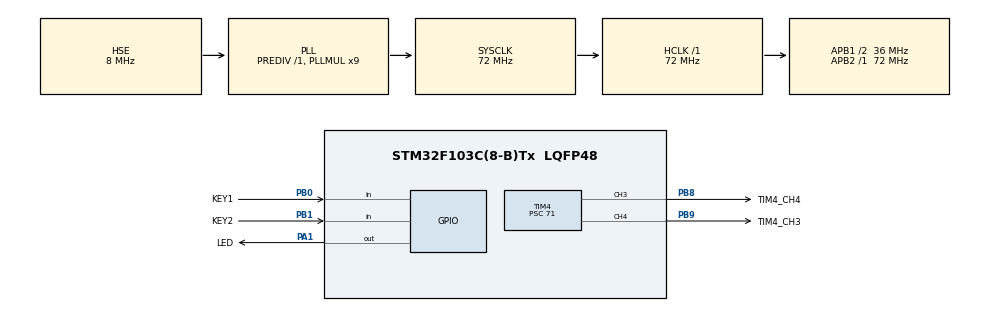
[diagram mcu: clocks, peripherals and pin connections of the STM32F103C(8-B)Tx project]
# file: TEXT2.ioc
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Mcu.Family=STM32F1
Mcu.Name=STM32F103C(8-B)Tx
Mcu.Package=LQFP48
NVIC.PriorityGroup=NVIC_PRIORITYGROUP_4
PA1.GPIO_Label=LED
PA1.PinState=GPIO_PIN_SET
PA1.Signal=GPIO_Output
PB0.GPIO_Label=KEY1
PB0.GPIO_PuPd=GPIO_PULLUP
PB0.Signal=GPIO_Input
PB1.GPIO_Label=KEY2
PB1.GPIO_PuPd=GPIO_PULLUP
PB1.Signal=GPIO_Input
PB8.GPIO_Label=TIM4_CH4
PB8.Signal=S_TIM4_CH3
PB9.GPIO_Label=TIM4_CH3
PB9.Signal=S_TIM4_CH4
PD0-OSC_IN.Mode=HSE-External-Oscillator
PD0-OSC_IN.Signal=RCC_OSC_IN
PD1-OSC_OUT.Mode=HSE-External-Oscillator
PD1-OSC_OUT.Signal=RCC_OSC_OUT
ProjectManager.HeapSize=0x200
ProjectManager.StackSize=0x400
ProjectManager.TargetToolchain=MDK-ARM V5.27
RCC.AHBFreq_Value=72000000
RCC.APB1CLKDivider=RCC_HCLK_DIV2
RCC.APB1Freq_Value=36000000
RCC.APB1TimFreq_Value=72000000
RCC.APB2Freq_Value=72000000
RCC.APB2TimFreq_Value=72000000
RCC.HCLKFreq_Value=72000000
RCC.PLLMUL=RCC_PLL_MUL9
RCC.PLLSourceVirtual=RCC_PLLSOURCE_HSE
RCC.SYSCLKFreq_VALUE=72000000
RCC.SYSCLKSource=RCC_SYSCLKSOURCE_PLLCLK
RCC.USBFreq_Value=72000000
SH.S_TIM4_CH3.0=TIM4_CH3,PWM Generation3 CH3
SH.S_TIM4_CH4.0=TIM4_CH4,PWM Generation4 CH4
TIM4.AutoReloadPreload=TIM_AUTORELOAD_PRELOAD_ENABLE
TIM4.Channel-PWM\ Generation3\ CH3=TIM_CHANNEL_3
TIM4.Channel-PWM\ Generation4\ CH4=TIM_CHANNEL_4
TIM4.OCFastMode_PWM-PWM\ Generation3\ CH3=TIM_OCFAST_ENABLE
TIM4.OCFastMode_PWM-PWM\ Generation4\ CH4=TIM_OCFAST_ENABLE
TIM4.OCPolarity_3=TIM_OCPOLARITY_LOW
TIM4.OCPolarity_4=TIM_OCPOLARITY_LOW
TIM4.Period=499
TIM4.Prescaler=71
VP_SYS_VS_ND.Mode=No_Debug
VP_TIM4_VS_ClockSourceINT.Mode=Internal
board=custom

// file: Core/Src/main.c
/* USER CODE BEGIN Header */
/**
  ******************************************************************************
  * @file           : main.c
  * @brief          : Main program body
  ******************************************************************************
  * @attention
  *
  * <h2><center>&copy; Copyright (c) 2025 STMicroelectronics.
  * All rights reserved.</center></h2>
  *
  * This software component is licensed by ST under BSD 3-Clause license,
  * the "License"; You may not use this file except in compliance with the
  * License. You may obtain a copy of the License at:
  *                        opensource.org/licenses/BSD-3-Clause
  *
  ******************************************************************************
  */
/* USER CODE END Header */
#include "main.h"
#include "tim.h"
#include "gpio.h"
#include "KEY.H"

void SystemClock_Config(void);

	unsigned char cnt=2;
	unsigned short i=0;
	unsigned char flag=0;
	void case0(unsigned char a){
		switch(a)
		{
		case 1:
			if(flag==0) i++;
			else i--;
			if(i>=400)flag=1;
			if(i<=0) flag=0;
			HAL_Delay(1);
			htim4.Instance->CCR3=i;
			htim4.Instance->CCR4=i;
			break;
		case 2:
			if(flag==0) i++;
			else i--;
			if(i>=100)flag=1;
			if(i<=0) flag=0;
			HAL_Delay(15);
			htim4.Instance->CCR3=i;
			htim4.Instance->CCR4=i;
			break;
		case 3:
			if(flag==0) i++;
			else i--;
			if(i>=20)flag=1;
			if(i<=0) flag=0;
			HAL_Delay(100);
			htim4.Instance->CCR3=i;
			htim4.Instance->CCR4=i;
			break;
		}
	}

int main(void)
{

  /* MCU Configuration--------------------------------------------------------*/

  /* Reset of all peripherals, Initializes the Flash interface and the Systick. */
  HAL_Init();

  /* Configure the system clock */
  SystemClock_Config();

  /* Initialize all configured peripherals */
  MX_GPIO_Init();
  MX_TIM4_Init();

  /* Infinite loop */
  while (1)
  {

    /* USER CODE BEGIN 3 */
		unsigned char key=KEY_GetVal();
		if(key==1)
		{
			cnt++;
			if(cnt>=3) cnt=3;

		}
		if(key==2)
		{
			cnt--;
			if(cnt<=1) cnt=1;
		}

		case0(cnt);
	}
  /* USER CODE END 3 */
}

void SystemClock_Config(void)
{
  RCC_OscInitTypeDef RCC_OscInitStruct = {0};
  RCC_ClkInitTypeDef RCC_ClkInitStruct = {0};

  /** Initializes the RCC Oscillators according to the specified parameters
  * in the RCC_OscInitTypeDef structure.
  */
  RCC_OscInitStruct.OscillatorType = RCC_OSCILLATORTYPE_HSE;
  RCC_OscInitStruct.HSEState = RCC_HSE_ON;
  RCC_OscInitStruct.HSEPredivValue = RCC_HSE_PREDIV_DIV1;
  RCC_OscInitStruct.HSIState = RCC_HSI_ON;
  RCC_OscInitStruct.PLL.PLLState = RCC_PLL_ON;
  RCC_OscInitStruct.PLL.PLLSource = RCC_PLLSOURCE_HSE;
  RCC_OscInitStruct.PLL.PLLMUL = RCC_PLL_MUL9;
  if (HAL_RCC_OscConfig(&RCC_OscInitStruct) != HAL_OK)
  {
    Error_Handler();
  }
  /** Initializes the CPU, AHB and APB buses clocks
  */
  RCC_ClkInitStruct.ClockType = RCC_CLOCKTYPE_HCLK|RCC_CLOCKTYPE_SYSCLK
                              |RCC_CLOCKTYPE_PCLK1|RCC_CLOCKTYPE_PCLK2;
  RCC_ClkInitStruct.SYSCLKSource = RCC_SYSCLKSOURCE_PLLCLK;
  RCC_ClkInitStruct.AHBCLKDivider = RCC_SYSCLK_DIV1;
  RCC_ClkInitStruct.APB1CLKDivider = RCC_HCLK_DIV2;
  RCC_ClkInitStruct.APB2CLKDivider = RCC_HCLK_DIV1;

  if (HAL_RCC_ClockConfig(&RCC_ClkInitStruct, FLASH_LATENCY_2) != HAL_OK)
  {
    Error_Handler();
  }
}

void Error_Handler(void)
{
}

/************************ (C) COPYRIGHT STMicroelectronics *****END OF FILE****/
